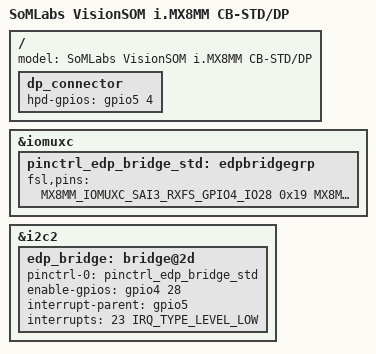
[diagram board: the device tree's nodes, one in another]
// SPDX-License-Identifier: GPL-2.0-or-later
/*
 * Copyright 2025 SomLabs
 *
 */

/dts-v1/;

#include "visionsom-8mm-cb-std.dtsi"
#include "visionsom-8mm-cb-dp.dtsi"

/ {
    model = "SoMLabs VisionSOM i.MX8MM CB-STD/DP";

    dp_connector {
        hpd-gpios = <&gpio5 4 GPIO_ACTIVE_HIGH>;
    };
};

&iomuxc {
    pinctrl_edp_bridge_std: edpbridgegrp {
        fsl,pins = <
            MX8MM_IOMUXC_SAI3_RXFS_GPIO4_IO28               0x19    /* ENABLE */
            MX8MM_IOMUXC_UART1_TXD_GPIO5_IO23               0x81    /* interrupt */
            MX8MM_IOMUXC_SPDIF_RX_GPIO5_IO4                 0x81    /* HPD */
        >;
    };
};

&i2c2 {

    /* MIPI-DSI to HDMI adapter */
    edp_bridge: bridge@2d {
        pinctrl-0 = <&pinctrl_edp_bridge_std>;
        enable-gpios = <&gpio4 28 GPIO_ACTIVE_HIGH>;
        interrupt-parent = <&gpio5>;
        interrupts = <23 IRQ_TYPE_LEVEL_LOW>;
    };
};
